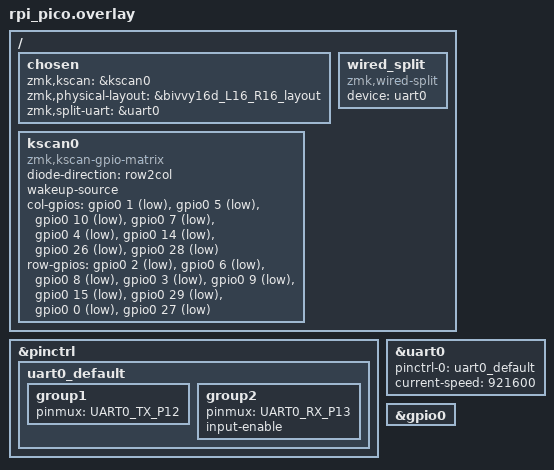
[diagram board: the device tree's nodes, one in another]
/*
 * Copyright (c) 2020 The ZMK Contributors
 *
 * SPDX-License-Identifier: MIT
 */

#include <dt-bindings/zmk/matrix_transform.h>
#include <physical_layouts.dtsi>
#include "bivvy16d-layouts.dtsi"

/* Define the TX/RX pins (GP12, GP13) for the wired link between left/right with RP2040 */
#include <dt-bindings/pinctrl/rpi-pico-rp2040-pinctrl.h>

&pinctrl {
    /* configuration for the usart0 "default" state */
    uart0_default: uart0_default {
        group1 {
            /* configure P12 as UART0 TX */
            pinmux = <UART0_TX_P12>;
            };
        group2 {
            /* configure P13 as UART0 RX */
            pinmux = <UART0_RX_P13>;
            /* enable input on pin 13 */
            input-enable;
        };
    };
};

&uart0 {
    pinctrl-0 = <&uart0_default>;
    pinctrl-names = "default";
    status = "okay";
    // Comment out for slower speeds if encountering issues.
    current-speed = <921600>;
};

&gpio0 {
    status = "okay";
};

/ {
    chosen {
        zmk,kscan = &kscan0;
        zmk,physical-layout = &bivvy16d_L16_R16_layout;
        zmk,split-uart = &uart0;
        // Other chosen items
    };

    /* By design, this is a reversible PCB so same wiring for left and right,
     * so can define the GPIOs once centrally.
     */

    kscan0: kscan0 {
        compatible = "zmk,kscan-gpio-matrix";
        diode-direction = "row2col";
        wakeup-source;

        col-gpios
            = <&gpio0 1 (GPIO_ACTIVE_LOW | GPIO_PULL_UP)>
            , <&gpio0 5 (GPIO_ACTIVE_LOW | GPIO_PULL_UP)>
            , <&gpio0 10 (GPIO_ACTIVE_LOW | GPIO_PULL_UP)>
            , <&gpio0 7 (GPIO_ACTIVE_LOW | GPIO_PULL_UP)>
            , <&gpio0 4 (GPIO_ACTIVE_LOW | GPIO_PULL_UP)>
            , <&gpio0 14 (GPIO_ACTIVE_LOW | GPIO_PULL_UP)>
            , <&gpio0 26 (GPIO_ACTIVE_LOW | GPIO_PULL_UP)>
            , <&gpio0 28 (GPIO_ACTIVE_LOW | GPIO_PULL_UP)>
            ;

        row-gpios
            = <&gpio0 2 GPIO_ACTIVE_LOW>
            , <&gpio0 6 GPIO_ACTIVE_LOW>
            , <&gpio0 8 GPIO_ACTIVE_LOW>
            , <&gpio0 3 GPIO_ACTIVE_LOW>
            , <&gpio0 9 GPIO_ACTIVE_LOW>
            , <&gpio0 15 GPIO_ACTIVE_LOW>
            , <&gpio0 29 GPIO_ACTIVE_LOW>
            , <&gpio0 0 GPIO_ACTIVE_LOW>
            , <&gpio0 27 GPIO_ACTIVE_LOW>
            ;
    };
};

/ {
    wired_split {
        compatible = "zmk,wired-split";
        device = <&uart0>;
    };
};

